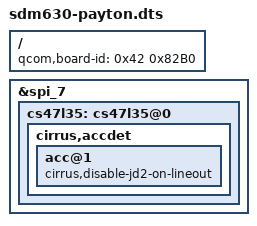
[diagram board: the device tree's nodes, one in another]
/dts-v1/;

// Moto X4 (payton) - P2B board revision
#include "sdm630-payton.dtsi"

/ {
	qcom,board-id = <0x42 0x82B0>;
};

&spi_7 {
	cs47l35: cs47l35@0 {
		cirrus,accdet {
			acc@1 {
				cirrus,disable-jd2-on-lineout;
			};
		};
	};
};
